# PIC32MZ1025W104132 device description
Architecture: MIPS; Family: PIC32MZW; Series: PIC32MZW
Registers are 32-bit, read-write, no defined reset value unless marked. A register's access mark holds for its fields unless they carry their own. Offsets are from the block's base; [hi:lo] are bit positions; 'fields as' and 'values as' point back to an identical list.

## RCON
Instances: RCON 0x1f801200 in periph_pb1a
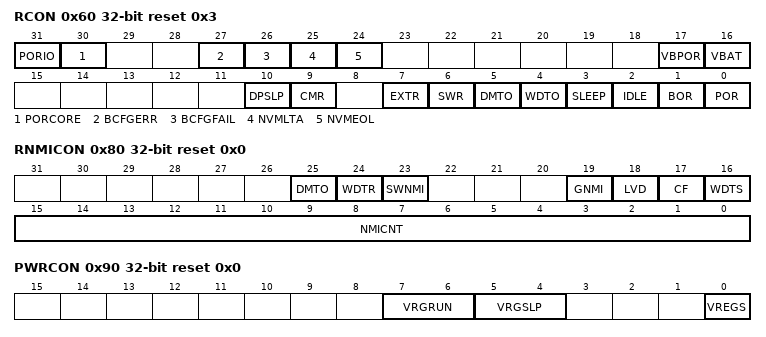
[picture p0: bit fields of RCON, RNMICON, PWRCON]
0x60 RCON reset 0x3 — RESET CONTROL REGISTER
  [31] PORIO — IO Voltage POR Flag bit
    1=A Power-up Reset has occurred due to IO Voltage; 0=A Power-up Reset has not occurred due to IO Voltage
  [30] PORCORE — Core Voltage POR Flag bit
    1=A Power-up Reset has occurred due to Core Voltage; 0=A Power-up Reset has not occurred due to Core Voltage
  [27] BCFGERR — BCFG Error Flag Bit
    0=A BCFG Error has not occurred; 1=A BCFG Error has occurred
  [26] BCFGFAIL — BCFG Failure Flag Bit
    0=A BCFG Failure has not occurred; 1=A BCFG Failure has occurred
  [25] NVMLTA — NVM Life Time Alert Flag Bit
    0=A NVM LTA Error has not occurred; 1=A NVM LTA Error has occurred
  [24] NVMEOL — NVM End of Life Flag Bit
    0=A NVM EOL Failure has not occurred; 1=A NVM EOL Failure has occurred
  [17] VBPOR — VBPOR Mode Flag Bit
    1=A VBAT Domain POR has occurred; 0=A VBAT Domain POR has not occurred
  [16] VBAT — VBAT Mode Flag Bit
    1=A POR exit from VBAT has occurred. A true POR must be established with the valid VBAT voltage level on the VBAT pin; 0=A POR exit from VBAT has not occurred
  [10] DPSLP — DPSLP Deep Sleep Mode Flag Bit
    1=Deep Sleep Mode has occurred; 0=Deep Sleep Mode has not occurred
  [9] CMR — Configuration Mismatch Flag bit
    1=A Configuration Mismatch Reset Event has occurred; 0=A Configuration Mismatch Reset Event has not occurred
  [7] EXTR — External Reset (MCLR) Status bit
    1=A Master Clear (pin) Reset has occurred; 0=A Master Clear (pin) Reset has not occurred
  [6] SWR — Software Reset Flag bit
    1=A Software Commanded Reset has occurred; 0=A Software Commanded Reset has not occurred
  [5] DMTO — Deadman Timer Time-Out Flag bit
    1=DMT Time-out has occurred and caused a reset; 0=DMT Time-out has not occurred
  [4] WDTO — Watchdog Timer Time-Out Flag bit
    1=WDT Time-out has occurred and caused a reset; 0=WDT Time-out has not occurred
  [3] SLEEP — Wake from Sleep Flag bit
    1=Device has been in Sleep mode; 0=Device has not been in Sleep mode
  [2] IDLE — Wake from Idle Flag bit
    1=Device was in Idle mode; 0=Device was not in Idle mode
  [1] BOR — Brown-out Reset Flag bit
    1=A Brown-out Reset has occurred; 0=A Brown-out Reset has not occurred
  [0] POR — Power-On Reset Flag bit
    1=A Power-up Reset has occurred; 0=A Power-up Reset has not occurred
0x70 RSWRST wo reset 0x0 — SOFTWARE RESET REGISTER
  [0] SWRST — Software Reset Trigger
    1=Enable software reset event; 0=Do not enable software reset event
0x80 RNMICON reset 0x0 — NMI CONTROL REGISTER
  [25] DMTO — Deadman Timer Time-Out Flag bit
    1=DMT Time-out has occurred and caused a NMI; 0=DMT Time-out has not occurred
  [24] WDTR — Watchdog Timer Time-Out in Run Flag bit
    1=WDT Time-out has occurred and caused a NMI; 0=WDT Time-out has not occurred
  [23] SWNMI — Software NMI Trigger
    1=Writing a 1 to this bit will cause an NMI to be generated; 0=Writing a 0 to this bit will have no effect
  [19] GNMI — External / Generic NMI Event
    1=A general NMI event has been detected and caused an NMI; 0=A general NMI event has not been detected
  [18] LVD — Programmable Low Voltage Detect Event
    1=PLVD has detected a low voltage condition and caused an NMI; 0=PLVD has not detected a low voltage condition
  [17] CF — Clock Fail Detect bit
    1=FSCM has detected clock failure and caused an NMI; 0=NO_FAILDET (FSCM has not detected clock failure)
  [16] WDTS — Watch-Dog Timer Time-Out in Sleep Flag bit
    1=WDT Time-out has occurred during sleep_mode and caused a wake-up from sleep; 0=WDT Time-out has not occurred during sleep_mode
  [15:0] NMICNT — NMI Reset counter value
    0=No delay between NMI assertion and device reset event; 1=1 sys_clk cycle that Software has to clear the NMI event before a device reset is performed; 2=2 sys_clk cycles that Software has to clear the NMI event before a device reset is performed; 0xffff=65535 sys_clk cycles that Software has to clear the NMI event before a device reset is performed
0x90 PWRCON reset 0x0 — POWER CONTROL REGISTER
  [7:6] VRGRUN — Controls Output level of the Voltage Regulators in Mission/Run Mode
    0=Main VREG Outputs are set to nominal voltage; 1=Main VREG Outputs are set to reduced voltage (approx 67% nominal); 2=Main VREG Outputs are set to reduced voltage (approx 83% Nominal); 3=Main VREG Outputs are set to nominal voltage
  [5:4] VRGSLP — Controls Output level of the Voltage Regulators During SLEEP Mode
    values as VRGRUN
  [0] VREGS — Voltage Regulator Standby Enable bit
    1=Main Voltage Regulator will remain active during Sleep; 0=Main Voltage Regulator will go to standby mode during Sleep
